# DA14531 register map
Vendor: Dialog; Series: DA14531; File version: 1.2
CPU: CM0 r1p0, little endian, MPU, FPU, 3 interrupt priority bits
Registers are 16-bit, read-write, reset 0x0 unless marked. A register's access mark holds for its fields unless they carry their own. Offsets are from the block's base; [hi:lo] are bit positions; {n}, {i} and the like mark numbered series; <NAME> marks a mode.

## RFMON — RFMON registers
Base 0x50003500
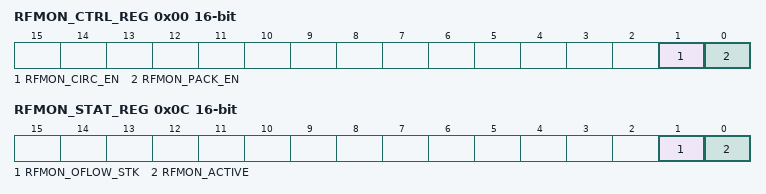
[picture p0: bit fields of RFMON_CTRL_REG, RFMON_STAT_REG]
0x00 RFMON_CTRL_REG
  [1] RFMON_CIRC_EN, [0] RFMON_PACK_EN
0x04 RFMON_ADDR_REG
  [15:2] RFMON_ADDR
0x08 RFMON_LEN_REG
  [13:0] RFMON_LEN
0x0C RFMON_STAT_REG
  [1] RFMON_OFLOW_STK, [0] RFMON_ACTIVE ro
0x10 RFMON_CRV_ADDR_REG
  [15:2] RFMON_CRV_ADDR ro
0x14 RFMON_CRV_LEN_REG
  [13:0] RFMON_CRV_LEN ro

## SYS_WDOG — SYS_WDOG registers
Base 0x50003100
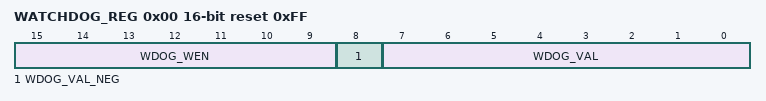
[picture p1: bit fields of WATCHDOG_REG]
0x00 WATCHDOG_REG reset 0xFF — Watchdog timer register.
  [15:9] WDOG_WEN wo — 0000.000 = Write enable for Watchdog timer else Write disable. This filter prevents unintentional presetting the watchdog with a SW run-away.
  [8] WDOG_VAL_NEG — 0 = Watchdog timer value is positive. 1 = Watchdog timer value is negative.
  [7:0] WDOG_VAL — Write: Watchdog timer reload value. Note that all bits 15-9 must be 0 to reload this register. Read: Actual Watchdog timer value. Decremented by 1 every 10.24 msec. Bit 8 indicates a negative counter value. 2, 1, 0, 1FF16, 1FE16 etc. An NMI or WDOG (SYS) reset is generated under the following conditions: If WATCHDOG_CTRL_REG[NMI_RST] = 0 then If WDOG_VAL = 0 -> NMI (Non Maskable Interrupt) if WDOG_VAL = 1F016 -> WDOG reset -> reload FF16 If WATCHDOG_CTRL_REG[NMI_RST] = 1 then if WDOG_VAL <= 0 -> WDOG reset -> reload FF16
0x02 WATCHDOG_CTRL_REG — Watchdog control register.
  [0] NMI_RST — 0 = Watchdog timer generates NMI at value 0, and WDOG (SYS) reset at <=-16. Timer can be frozen /resumed using SET_FREEZE_REG[FRZ_WDOG]/ RESET_FREEZE_REG[FRZ_WDOG]. 1 = Watchdog timer generates a WDOG (SYS) reset at value 0 and can not be frozen by Software. Note that this bit can only be set to 1 by SW and only be reset with a WDOG (SYS) reset or SW reset. The watchdog is always frozen when the Cortex-M0 is halted in DEBUG State.

## TIMER0 — TIMER0 registers
Base 0x50003400
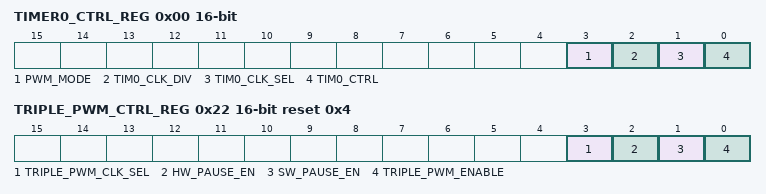
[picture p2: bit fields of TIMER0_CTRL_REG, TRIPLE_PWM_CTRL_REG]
0x00 TIMER0_CTRL_REG — Timer0 control register
  [3] PWM_MODE — 0 = PWM signals are '1' during high time. 1 = PWM signals send out the (fast) clock divided by 2 during high time. So it will be in the range of 1 to 8 MHz.
  [2] TIM0_CLK_DIV — 1 = Timer0 uses selected clock frequency as is. 0 = Timer0 uses selected clock frequency divided by 10. Note that this applies only to the ON-counter.
  [1] TIM0_CLK_SEL — 1 = Timer0 uses 16, 8, 4 or 2 MHz (fast) clock frequency. 0 = Timer0 uses LP clock
  [0] TIM0_CTRL — 0 = Timer0 is off and in reset state. 1 = Timer0 is running.
0x02 TIMER0_ON_REG — Timer0 on control register
  [15:0] TIM0_ON — Timer0 On reload value: If read the actual ON-counter value is returned
0x04 TIMER0_RELOAD_M_REG — 16 bits reload value for Timer0
  [15:0] TIM0_M — Timer0 'high' reload value If read the actual T0-counter value is returned
0x06 TIMER0_RELOAD_N_REG — 16 bits reload value for Timer0
  [15:0] TIM0_N — Timer0 'low' reload value: If read the actual T0-counter value is returned
0x08 TRIPLE_PWM_FREQUENCY — Frequency for PWM 2,3,4,5,6 and 7
  [13:0] PWM_FREQ — Defines the frequeancy of PWM 2,3,4,5,,6 and 7. pwm freq = module Frequency / (value+1) module frequency is the LP_CLK when TRIPLE_PWM_CLK_SEL=0 else is the sys_clk divided by TMR_DIV
{0x6+2i} PWM{i}_START_CYCLE (i=2..7) — Defines start Cycle for PWM{i}
  [13:0] START_CYCLE — Defines the cycle in which the PWM becomes high. if start_cycle is larger than freq or end_cycle is equal to start_cycle, pwm out is always 0
{0x12+2i} PWM{i}_END_CYCLE (i=2..7) — Defines end Cycle for PWM{i}
  [13:0] END_CYCLE — Defines the cycle in which the PWM becomes low. If end_cycle is larger then freq and start_cycle is not larger then freq, output is always 1
0x22 TRIPLE_PWM_CTRL_REG reset 0x4 — PWM 2,3,4,5,6,7 Control
  [3] TRIPLE_PWM_CLK_SEL — 1 = Timer2 uses 16, 8, 4 or 2 MHz (fast) clock frequency. 0 = Timer2 uses LP clock
  [2] HW_PAUSE_EN — '1' = HW can pause PWM 2,3,4,5,6,7
  [1] SW_PAUSE_EN — '1' = PWM 2 3 4 5 6 7 are paused
  [0] TRIPLE_PWM_ENABLE — '1' = enable PWM 2 3 4 5 6 7

## WKUP — WKUP registers
Base 0x50000100
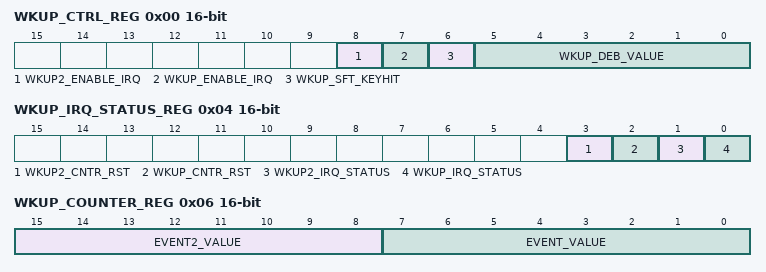
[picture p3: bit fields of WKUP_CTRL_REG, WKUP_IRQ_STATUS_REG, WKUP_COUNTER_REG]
0x00 WKUP_CTRL_REG — Control register for the wakeup counter
  [8] WKUP2_ENABLE_IRQ — 0 = no interrupt will be generated 1 = if the event counter2 reaches the value set by WKUP_COMPARE_REG an IRQ will be generated
  [7] WKUP_ENABLE_IRQ — 0 = no interrupt will be generated 1 = if the event counter reaches the value set by WKUP_COMPARE_REG an IRQ will be generated
  [6] WKUP_SFT_KEYHIT — 0 = no effect 1 = emulate key hit. The event counter and counter2 will increment by 1 (after debouncing if enabled). First make this bit 0 before any new key hit can be sensed.
  [5:0] WKUP_DEB_VALUE — Keyboard debounce time (N*1 ms with N = 1 to 63). 0x0: no debouncing 0x1 to 0x3F: 1 ms to 63 ms debounce time
0x02 WKUP_COMPARE_REG — Number of events before wakeup interrupt
  [7:0] WKUP_COMPARE — Defines the number of events -1 that have to be counted before the wakeup interrupt will be given. value 0 means one event.
0x04 WKUP_IRQ_STATUS_REG — Reset wakeup interrupt
  [3] WKUP2_CNTR_RST wo — writing 1 will reset the event2 counter
  [2] WKUP_CNTR_RST wo — writing 1 will reset the event counter
  [1] WKUP2_IRQ_STATUS — Gives 1 when there is a wkup2 pending IRQ. Writing 1 will reset the interrupt.
  [0] WKUP_IRQ_STATUS — Gives 1 when there is a wkup pending IRQ. Writing 1 will reset the interrupt.
0x06 WKUP_COUNTER_REG — Actual number of events of the wakeup counter
  [15:8] EVENT2_VALUE ro — This value represents the number of events that have been counted so far. It will be reset by resetting the interrupt.
  [7:0] EVENT_VALUE ro — This value represents the number of events that have been counted so far. It will be reset by resetting the interrupt.
0x08 WKUP_SELECT_GPIO_REG — Select which inputs from P0 port can trigger wkup counter
  [11:0] WKUP_SELECT_GPIO — 0 = input P0x is not enabled for wakeup event counter 1 = input P0x is enabled for wakeup event counter
0x0A WKUP2_SELECT_GPIO_REG — Select which inputs from P1 port can trigger wkup counter
  [11:0] WKUP2_SELECT_GPIO — 0 = input P0x is not enabled for wakeup event counter 1 = input P0x is enabled for wakeup event counter
0x0C WKUP_POL_GPIO_REG — Select the sensitivity polarity for each P0 input
  [11:0] WKUP_POL_GPIO — 0 = the enabled input P0x increments the event counter if that input goes high 1 = the enabled input P0x increments the event counter if that input goes low
0x0E WKUP2_POL_GPIO_REG — Select the sensitivity polarity for each P1 input
  [11:0] WKUP2_POL_GPIO — 0 = the enabled input P0x increments the event2 counter if that input goes high 1 = the enabled input P0x increments the event2 counter if that input goes low
